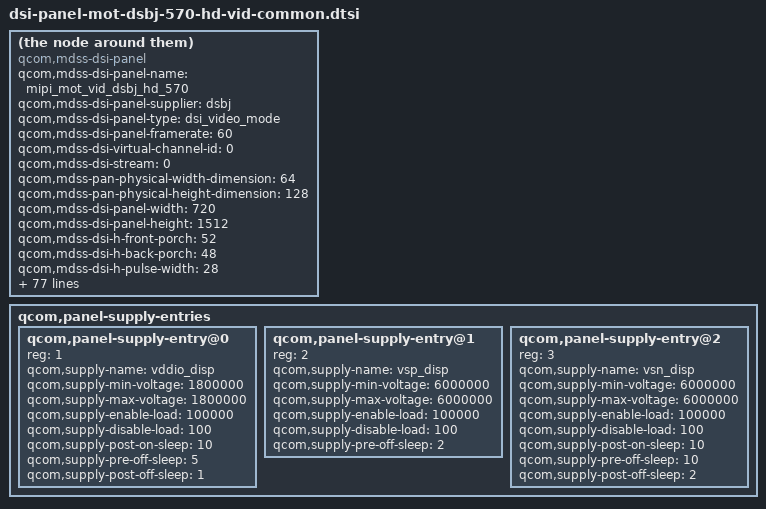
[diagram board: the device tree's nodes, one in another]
/* Copyright (c) 2016, The Linux Foundation. All rights reserved.
 *
 * This program is free software; you can redistribute it and/or modify
 * it under the terms of the GNU General Public License version 2 and
 * only version 2 as published by the Free Software Foundation.
 *
 * This program is distributed in the hope that it will be useful,
 * but WITHOUT ANY WARRANTY; without even the implied warranty of
 * MERCHANTABILITY or FITNESS FOR A PARTICULAR PURPOSE.  See the
 * GNU General Public License for more details.
 */

compatible = "qcom,mdss-dsi-panel";
qcom,mdss-dsi-panel-name = "mipi_mot_vid_dsbj_hd_570";
qcom,mdss-dsi-panel-supplier = "dsbj";
qcom,mdss-dsi-panel-type = "dsi_video_mode";
qcom,mdss-dsi-panel-framerate = <60>;
qcom,mdss-dsi-virtual-channel-id = <0>;
qcom,mdss-dsi-stream = <0>;
qcom,mdss-pan-physical-width-dimension = <64>;
qcom,mdss-pan-physical-height-dimension = <128>;
qcom,mdss-dsi-panel-width = <720>;
qcom,mdss-dsi-panel-height = <1512>;
qcom,mdss-dsi-h-front-porch = <52>;
qcom,mdss-dsi-h-back-porch = <48>;
qcom,mdss-dsi-h-pulse-width = <28>;
qcom,mdss-dsi-h-sync-skew = <0>;
qcom,mdss-dsi-v-back-porch = <20>;
qcom,mdss-dsi-v-front-porch = <41>;
qcom,mdss-dsi-v-pulse-width = <4>;
qcom,mdss-dsi-h-left-border = <0>;
qcom,mdss-dsi-h-right-border = <0>;
qcom,mdss-dsi-v-top-border = <0>;
qcom,mdss-dsi-v-bottom-border = <0>;
qcom,mdss-dsi-bpp = <24>;
qcom,mdss-dsi-underflow-color = <0xff>;
qcom,mdss-dsi-border-color = <0>;
qcom,mdss-dsi-on-command = [
			39 01 00 00 00 00 04 FF 98 81 0e
			15 01 00 00 00 00 02 46 5d
			15 01 00 00 00 00 02 4d 93
			15 01 00 00 00 00 02 d4 80
			15 01 00 00 00 00 02 02 10
			15 01 00 00 00 00 02 4b 13
			39 01 00 00 00 00 04 FF 98 81 06
			15 01 00 00 00 00 02 13 77
			15 01 00 00 00 00 02 14 41
			15 01 00 00 00 00 02 15 23
			15 01 00 00 00 00 02 16 41
			15 01 00 00 00 00 02 17 ff
			15 01 00 00 00 00 02 18 00
			15 01 00 00 00 00 02 3e 62
			39 01 00 00 00 00 04 FF 98 81 0c
			15 01 00 00 00 00 02 00 18
			15 01 00 00 00 00 02 01 67
			15 01 00 00 00 00 02 02 19
			15 01 00 00 00 00 02 03 6a
			15 01 00 00 00 00 02 04 18
			15 01 00 00 00 00 02 05 66
			15 01 00 00 00 00 02 06 1a
			15 01 00 00 00 00 02 07 70
			15 01 00 00 00 00 02 08 19
			15 01 00 00 00 00 02 09 6e
			15 01 00 00 00 00 02 0a 18
			15 01 00 00 00 00 02 0b 63
			15 01 00 00 00 00 02 0c 19
			15 01 00 00 00 00 02 0d 6d
			15 01 00 00 00 00 02 0e 18
			15 01 00 00 00 00 02 0f 64
			15 01 00 00 00 00 02 10 1a
			15 01 00 00 00 00 02 11 72
			15 01 00 00 00 00 02 12 19
			15 01 00 00 00 00 02 13 6b
			15 01 00 00 00 00 02 14 1a
			15 01 00 00 00 00 02 15 73
			15 01 00 00 00 00 02 16 19
			15 01 00 00 00 00 02 17 69
			15 01 00 00 00 00 02 18 18
			15 01 00 00 00 00 02 19 61
			15 01 00 00 00 00 02 1a 18
			15 01 00 00 00 00 02 1b 62
			15 01 00 00 00 00 02 1c 1a
			15 01 00 00 00 00 02 1d 6f
			15 01 00 00 00 00 02 1e 19
			15 01 00 00 00 00 02 1f 6c
			15 01 00 00 00 00 02 20 18
			15 01 00 00 00 00 02 21 65
			15 01 00 00 00 00 02 22 18
			15 01 00 00 00 00 02 23 60
			15 01 00 00 00 00 02 24 19
			15 01 00 00 00 00 02 25 68
			15 01 00 00 00 00 02 26 1a
			15 01 00 00 00 00 02 27 71
			39 01 00 00 00 00 04 FF 98 81 00
			39 01 00 00 00 00 03 51 00 00
			15 01 00 00 00 00 02 53 2C
			15 01 00 00 05 00 02 55 00
			05 01 00 00 78 00 02 11 00
			39 01 00 00 00 00 04 FF 98 81 03
			15 01 00 00 00 00 02 83 20
			15 01 00 00 05 00 02 84 02
			15 01 00 00 05 00 02 BC 08
			39 01 00 00 00 00 04 FF 98 81 06
			15 01 00 00 00 00 02 06 C4
			39 01 00 00 00 00 04 FF 98 81 01
			15 01 00 00 00 00 02 2d 60
			39 01 00 00 00 00 04 FF 98 81 00
			05 01 00 00 14 00 02 29 00];
qcom,mdss-dsi-off-command = [
			05 01 00 00 14 00 01 28
			05 01 00 00 78 00 01 10];


qcom,mdss-dsi-on-command-state = "dsi_lp_mode";
qcom,mdss-dsi-off-command-state = "dsi_lp_mode";

qcom,mdss-dsi-cabc-ui-command = [15 01 00 00 05 00 02 55 01];
qcom,mdss-dsi-cabc-ui-command-state = "dsi_hs_mode";
qcom,mdss-dsi-cabc-mv-command = [15 01 00 00 00 00 02 55 03];
qcom,mdss-dsi-cabc-mv-command-state = "dsi_hs_mode";
qcom,mdss-dsi-cabc-dis-command = [15 01 00 00 00 00 02 55 00];
qcom,mdss-dsi-cabc-dis-command-state = "dsi_hs_mode";
qcom,mdss-dsi-hbm-on-command = [39 01 00 00 00 00 03 51 0F FF];
qcom,mdss-dsi-hbm-on-command-state = "dsi_hs_mode";
qcom,mdss-dsi-hbm-off-command = [39 01 00 00 00 00 03 51 0F FF];
qcom,mdss-dsi-hbm-off-command-state = "dsi_hs_mode";
qcom,mdss-dsi-hbm-type = "lcd-dcs-gpio";

qcom,mdss-dsi-h-sync-pulse = <1>;
qcom,mdss-dsi-traffic-mode = "burst_mode";
qcom,mdss-dsi-bllp-eof-power-mode;
qcom,mdss-dsi-bllp-power-mode;
qcom,mdss-dsi-lane-0-state;
qcom,mdss-dsi-lane-1-state;
qcom,mdss-dsi-lane-2-state;
qcom,mdss-dsi-lane-3-state;
qcom,mdss-dsi-panel-timings-phy-v2 = [
		1F 1C 04 06 03 03 04 a0
		1F 1C 04 06 03 03 04 a0
		1F 1C 04 06 03 03 04 a0
		1F 1C 04 06 03 03 04 a0
		1F 0F 04 05 03 03 04 a0];
qcom,mdss-dsi-t-clk-post = <0x0b>;
qcom,mdss-dsi-t-clk-pre = <0x24>;
qcom,mdss-dsi-bl-min-level = <1>;
qcom,mdss-dsi-bl-max-level = <4095>;
qcom,mdss-dsi-dma-trigger = "trigger_sw";
qcom,mdss-dsi-mdp-trigger = "none";
qcom,mdss-dsi-bl-pmic-control-type = "bl_ctrl_dcs";
qcom,mdss-dsi-bl-dcs-command-state = "dsi_hs_mode";
qcom,bklt-dcs-2bytes-enabled;
qcom,mdss-dsi-reset-sequence = <1 10>, <0 10>, <1 10>;
qcom,mdss-dsi-lp11-init;
qcom,mdss-dsi-tx-eot-append;
qcom,mdss-dsi-init-delay-us = <7000>;
qcom,mdss-dsi-no-panel-on-read-support;
//qcom,mdss-dsi-lp11-lcdb-reset;
qcom,mdss-panel-off-rst-disable;
//qcom,mdss-panel-reset-high;
qcom,esd-check-enabled;
qcom,mdss-dsi-panel-status-command = [06 01 00 01 05 00 01 0A];
qcom,mdss-dsi-panel-status-command-state = "dsi_lp_mode";
qcom,mdss-dsi-panel-status-check-mode = "reg_read";
qcom,mdss-dsi-panel-status-value = <0x9C>;
qcom,mdss-dsi-panel-status-read-length = <1>;
qcom,mdss-dsi-panel-status-valid-params = <1>;
qcom,mdss-dsi-panel-status-command-mode = "dsi_lp_mode";


qcom,panel-supply-entries {
	#address-cells = <1>;
	#size-cells = <0>;

	qcom,panel-supply-entry@0 {
		reg = <1>;
		qcom,supply-name = "vddio_disp";
		qcom,supply-min-voltage = <1800000>;
		qcom,supply-max-voltage = <1800000>;
		qcom,supply-enable-load = <100000>;
		qcom,supply-disable-load = <100>;
		qcom,supply-post-on-sleep = <10>;
		qcom,supply-pre-off-sleep = <5>;
		qcom,supply-post-off-sleep = <1>;
	};

	qcom,panel-supply-entry@1 {
		reg = <2>;
		qcom,supply-name = "vsp_disp";
		qcom,supply-min-voltage = <6000000>;
		qcom,supply-max-voltage = <6000000>;
		qcom,supply-enable-load = <100000>;
		qcom,supply-disable-load = <100>;
		qcom,supply-pre-off-sleep = <2>;
	};

	qcom,panel-supply-entry@2 {
		reg = <3>;
		qcom,supply-name = "vsn_disp";
		qcom,supply-min-voltage = <6000000>;
		qcom,supply-max-voltage = <6000000>;
		qcom,supply-enable-load = <100000>;
		qcom,supply-disable-load = <100>;
		qcom,supply-post-on-sleep = <10>;
		qcom,supply-pre-off-sleep = <10>;
		qcom,supply-post-off-sleep = <2>;
	};
};
